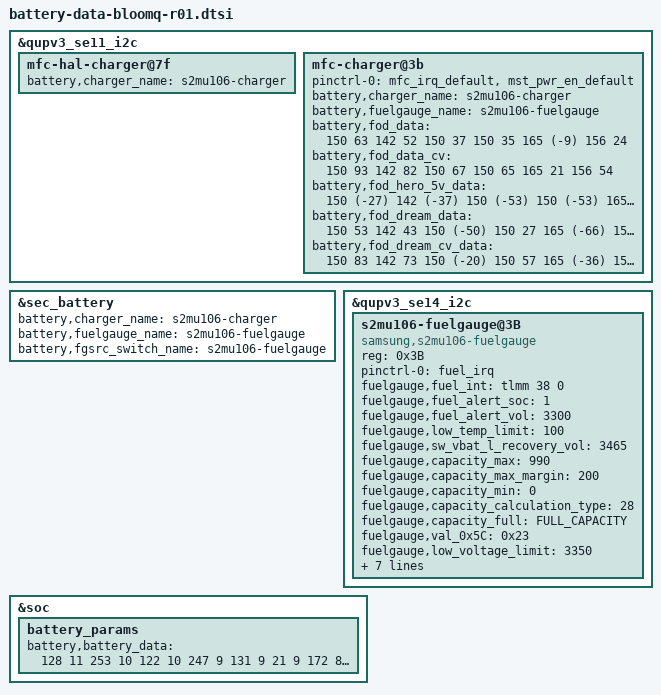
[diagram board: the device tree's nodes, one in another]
/* Copyright (c) 2014, The Linux Foundation. All rights reserved.
 *
 * This program is free software; you can redistribute it and/or modify
 * it under the terms of the GNU General Public License version 2 and
 * only version 2 as published by the Free Software Foundation.
 *
 * This program is distributed in the hope that it will be useful,
 * but WITHOUT ANY WARRANTY; without even the implied warranty of
 * MERCHANTABILITY or FITNESS FOR A PARTICULAR PURPOSE.  See the
 * GNU General Public License for more details.
 */

/* This dtsi is for hw rev to 01 */
#include "battery-data-bloomq-common.dtsi"

&qupv3_se11_i2c {
	mfc-hal-charger@7f {
		battery,charger_name = "s2mu106-charger";
	};
	mfc-charger@3b {
		pinctrl-0 = <&mfc_irq_default &mst_pwr_en_default>;

		battery,charger_name = "s2mu106-charger";
		battery,fuelgauge_name = "s2mu106-fuelgauge";

		battery,fod_data = <150 63 142 52 150 37 150 35 165 (-9) 156 24>;
		battery,fod_data_cv = <150 93 142 82 150 67 150 65 165 21 156 54>;
		battery,fod_hero_5v_data = <150 (-27) 142 (-37) 150 (-53) 150 (-53) 165 160 156 (-61)>;
		battery,fod_dream_data = <150 53 142 43 150 (-50) 150 27 165 (-66) 156 19>;
		battery,fod_dream_cv_data = <150 83 142 73 150 (-20) 150 57 165 (-36) 156 49>;
	};
};

&sec_battery {
	battery,charger_name = "s2mu106-charger";
	battery,fuelgauge_name = "s2mu106-fuelgauge";
	battery,fgsrc_switch_name = "s2mu106-fuelgauge"; /* Fuelgauge voltage source */
};

&qupv3_se14_i2c {
	status = "ok";

	s2mu106-fuelgauge@3B {
		compatible = "samsung,s2mu106-fuelgauge";
		reg = <0x3B>;
		pinctrl-names = "default";
		pinctrl-0 = <&fuel_irq>;
		fuelgauge,fuel_int = <&tlmm 38 0>;
		fuelgauge,fuel_alert_soc = <1>;
		fuelgauge,fuel_alert_vol = <3300>;
		fuelgauge,low_temp_limit = <100>;
		fuelgauge,sw_vbat_l_recovery_vol = <3465>;
		fuelgauge,capacity_max = <990>;
		fuelgauge,capacity_max_margin = <200>;
		fuelgauge,capacity_min = <0>;
		fuelgauge,capacity_calculation_type = <28>;
		fuelgauge,capacity_full = <FULL_CAPACITY>;
//		fuelgauge,type_str = "SDI";
//		fuelgauge,model_type = <1>;
//		fuelgauge,fg_log_enable = <1>;
		fuelgauge,val_0x5C = <0x21>;
		fuelgauge,low_voltage_limit = <3350>;
		fuelgauge,low_voltage_limit_lowtemp = <3200>;
		fuelgauge,low_voltage_recover_lowtemp = <3480>;
		fuelgauge,low_voltage_limit_cnt = <2>;
		fuelgauge,i_socr_coeff = <0>;

		fuelgauge,ttf_capacity = <FULL_CAPACITY>;
		fuelgauge,cv_data = <
			2488	829	1809
			2409	832	1796
			2327	837	1769
			2272	840	1743
			2182	846	1721
			2104	850	1690
			2038	854	1670
			1950	859	1640
			1904	861	1622
			1838	865	1594
			1797	867	1576
			1749	870	1560
			1703	873	1531
			1683	873	1525
			1667	875	1515
			1660	875	1512
			1653	876	1509
			1615	878	1502
			1580	880	1483
			1553	881	1463
			1544	882	1458
			1520	883	1451
			1477	886	1424
			1431	888	1409
			1396	891	1383
			1347	894	1361
			1299	896	1332
			1267	898	1315
			1231	902	1288
			1202	904	1263
			1148	906	1243
			1109	909	1213
			1067	911	1185
			1031	914	1156
			1013	915	1140
			975	917	1111
			961	919	1084
			921	921	1064
			892	923	1038
			887	923	1019
			863	925	1004
			833	927	976
			808	929	946
			787	930	918
			780	931	904
			764	932	895
			744	934	864
			730	935	846
			715	936	828
			693	937	800
			681	938	783
			666	940	752
			651	941	735
			640	942	712
			628	945	697
			622	946	679
			618	947	664
			600	950	646
			596	951	627
			589	953	614
			584	953	601
			576	956	572
			577	957	553
			562	958	535
			511	968	506
			505	969	487
			493	971	464
			492	972	435
			484	973	417
			480	975	398
			474	976	380
			470	977	364
			462	977	355
			456	978	336
			452	979	329
			446	981	303
			437	982	282
			429	984	255
			423	985	242
			422	986	229
			414	987	211
			411	988	199
			405	989	191
			397	990	171
			391	991	140
			387	992	126
			384	993	107
			372	995	84
			364	997	54
			356	998	26
			356	998	13
			0	1000	0
			>;
	};
};
&soc {
battery_params {
		battery,battery_data =
			<
			/***** battery data for 4.4 *****/
			/* battery,battery_table3 */
			128 11 253 10 122 10 247 9 131 9
			21 9 172 8 70 8 204 7 147 7
			50 7 217 6 164 6 124 6 92 6
			65 6 34 6 249 5 196 5 144 5
			246 4 114 1 163 8 56 8 205 7
			97 7 246 6 139 6 32 6 180 5
			73 5 222 4 114 4 7 4 156 3
			48 3 197 2 90 2 238 1 131 1
			24 1 172 0 65 0 214 15

			/* battery,battery_table4 */
			20 20 20 59 59 59 59 60 60 59
			59 59 59 60 60 61 63 64 67 72
			86 255

			/* battery,batcap */
			0x00 0x30 0xE2 0x19 /* [0x0E] [0x0F] [0x10] [0x11] */
			/* battery,accum */ 
			0x00 0x08 /* [0x44] [0x45] */

			/* battery,soc_arr_val */
			10976 10448 9920 9393 8866 8338 7811 7284 6756 6229
			5702 5174 4647 4120 3592 3064 2537 2010 1482 955
			428 (-88)

			/* battery,ocv_arr_val */
			44630 43985 43340 42696 42086 41503 40951 40442 39950 39560
			39066 38612 38343 38137 37978 37853 37678 37469 37219 36936
			36711 32346

			/* battery,tunning */
			0x00

			/***** battery data for 4.33 *****/
			/* battery,battery_table3 */
			76 11 200 10 68 10 193 9 79 9
			227 8 135 8 251 7 186 7 119 7
			35 7 198 6 147 6 110 6 82 6
			59 6 31 6 247 5 196 5 144 5
			245 4 162 1 240 8 130 8 20 8
			165 7 55 7 201 6 90 6 236 5
			126 5 16 5 161 4 51 4 197 3
			87 3 232 2 122 2 12 2 157 1
			47 1 193 0 83 0 228 15

			/* battery,battery_table4 */
			47 47 47 47 47 47 47 48 47 47
			47 47 47 47 48 48 49 50 51 53
			58 95

			/* battery,batcap */
			0xC8 0x4B 0xF2 0x12 /* [0x0E] [0x0F] [0x10] [0x11] */
			/* battery,accum */
			0x00 0x8 /* [0x44] [0x45] */

			/* battery,soc_arr_val */
			11172 10633 10096 9557 9019 8480 7942 7403 6865 6327 
			5788 5250 4711 4173 3634 3096 2558 2019 1481 942
			404 (-135)
			/* battery,ocv_arr_val */
			44121 43477 42833 42192 41634 41106 40660 39975 39657 39330
			38921 38466 38219 38038 37900 37787 37652 37457 37206 36955
			36198 32039

			/* battery,tunning */
			0x00

			/***** battery data for 4.31 *****/
			/* battery,battery_table3 */
			76 11 200 10 68 10 193 9 79 9
			227 8 135 8 251 7 186 7 119 7
			35 7 198 6 147 6 110 6 82 6 
			59 6 31 6 247 5 196 5 144 5
			245 4 162 1 24 9 168 8 56 8
			199 7 87 7 231 6 119 6 7 6
			150 5 38 5 182 4 70 4 214 3
			102 3 245 2 133 2 21 2 165 1
			53 1 196 0 84 0 228 15

			/* battery,battery_table4 */
			47 47 47 47 47 47 47 48 47 47
			47 47 47 47 48 48 49 50 51 53
			58 95

			/* battery,batcap */
			0x38 0x4A 0x8E 0x12 /* [0x0E] [0x0F] [0x10] [0x11] */
			/* battery,accum */
			0x00 0x8 /* [0x44] [0x45] */

			/* battery,soc_arr_val */
			11368 10820 10271 9724 9176 8628 8081 7533 6985 6437
			5889 5341 4794 4246 3698 3150 2602 2054 1507 959
			411 (-137)

			/* battery,ocv_arr_val */
			44121 43477 42833 42192 41634 41106 40660 39975 39657 39330
			38921 38466 38219 38038 37900 37787 37652 37457 37206 36955
			36198 32039

			/* battery,tunning */
			0x00

			/***** battery data for 4.29 *****/
			/* battery,battery_table3 */
			76 11 200 10 68 10 193 9 79 9
			227 8 135 8 251 7 186 7 119 7
			35 7 198 6 147 6 110 6 82 6
			59 6 31 6 247 5 196 5 144 5
			245 4 162 1 71 9 212 8 98 8
			239 7 125 7 11 7 152 6 38 6
			179 5 65 5 206 4 92 4 233 3
			119 3 4 3 146 2 32 2 173 1
			59 1 200 0 86 0 227 15

			/* battery,battery_table4 */
			47 47 47 47 47 47 47 48 47 47
			47 47 47 47 48 48 49 50 51 53
			58 95

			/* battery,batcap */
			0xA8 0x48 0x2A 0x12 /* [0x0E] [0x0F] [0x10] [0x11] */
			/* battery,accum */
			0x00 0x8 /* [0x44] [0x45] */

			/* battery,soc_arr_val */
			11596 11036 10478 9919 9360 8802 8243 7684 7125 6566
			6007 5449 4890 4331 3772 3212 2654 2096 1537 978
			419 (-140)

			/* battery,ocv_arr_val */
			44121 43477 42833 42192 41634 41106 40660 39975 39657 39330
			38921 38466 38219 38038 37900 37787 37652 37457 37206 36955
			36198 32039

			/* battery,tunning */
			0x00

			/***** battery data for 4.24 *****/
			/* battery,battery_table3 */
			76 11 200 10 68 10 193 9 79 9
			227 8 135 8 251 7 186 7 119 7
			35 7 198 6 147 6 110 6 82 6
			59 6 31 6 247 5 196 5 144 5
			245 4 162 1 196 9 76 9 211 8
			91 8 226 7 106 7 241 6 121 6
			0 6 136 5 15 5 151 4 30 4
			166 3 45 3 181 2 60 2 196 1
			75 1 211 0 90 0 226 15

			/* battery,battery_table4 */
			47 47 47 47 47 47 47 48 47 47
			47 47 47 47 48 48 49 50 51 53
			58 95

			/* battery,batcap */
			0x88 0x45 0x62 0x11 /* [0x0E] [0x0F] [0x10] [0x11] */
			/* battery,accum */
			0x00 0x8 /* [0x44] [0x45] */

			/* battery,soc_arr_val */
			12208 11619 11031 10443 9854 9266 8678 8088 7501 6913
			6324 5736 5148 4559 3971 3383 2795 2206 1618 1030
			441 (-147)
			/* battery,ocv_arr_val */
			44121 43477 42833 42192 41634 41106 40660 39975 39657 39330
			38921 38466 38219 38038 37900 37787 37652 37457 37206 36955
			36198 32039

			/* battery,tunning */
			0x00
			>;
	};
};

&qupv3_se14_i2c {
	s2mu106-fuelgauge@3B {
		fuelgauge,val_0x5C = <0x23>;
	};
};
